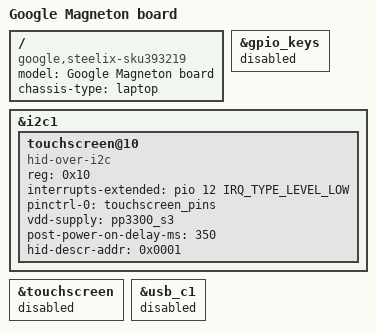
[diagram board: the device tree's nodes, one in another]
// SPDX-License-Identifier: (GPL-2.0 OR MIT)
/*
 * Copyright 2022 Google LLC
 */

/dts-v1/;
#include "mt8186-corsola-steelix.dtsi"

/ {
	model = "Google Magneton board";
	compatible = "google,steelix-sku393219", "google,steelix-sku393216",
		     "google,steelix", "mediatek,mt8186";
	chassis-type = "laptop";
};

&gpio_keys {
	status = "disabled";
};

&i2c1 {
	touchscreen@10 {
		compatible = "hid-over-i2c";
		reg = <0x10>;
		interrupts-extended = <&pio 12 IRQ_TYPE_LEVEL_LOW>;
		pinctrl-names = "default";
		pinctrl-0 = <&touchscreen_pins>;
		vdd-supply = <&pp3300_s3>;
		post-power-on-delay-ms = <350>;
		hid-descr-addr = <0x0001>;
	};
};

&touchscreen {
	status = "disabled";
};

&usb_c1 {
	status = "disabled";
};
